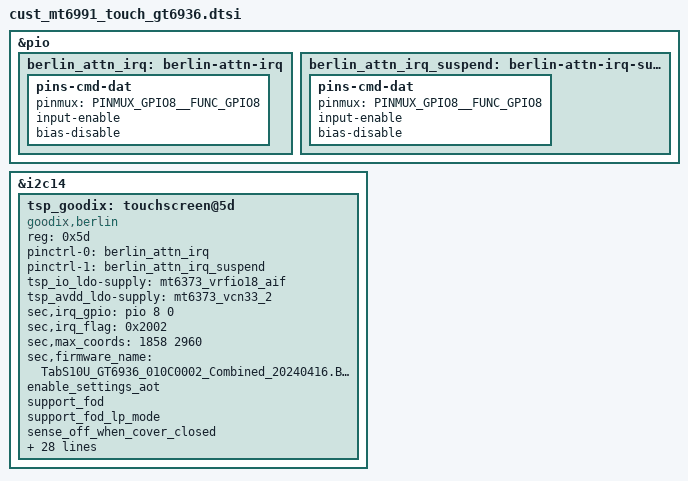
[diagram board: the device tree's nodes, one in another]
// SPDX-License-Identifier: GPL-2.0
/*
 * Copyright (c) 2019 MediaTek Inc.
 */

&pio {
	berlin_attn_irq: berlin-attn-irq {
		pins-cmd-dat {
			pinmux = <PINMUX_GPIO8__FUNC_GPIO8>;
			input-enable;
			bias-disable;
		};
	};

	berlin_attn_irq_suspend: berlin-attn-irq-suspend {
		pins-cmd-dat {
			pinmux = <PINMUX_GPIO8__FUNC_GPIO8>;
			input-enable;
			bias-disable;
		};
	};
};

&i2c14 {
	#address-cells = <1>;
	#size-cells = <0>;
	status = "okay";

	tsp_goodix: touchscreen@5d {
		status = "okay";
		compatible = "goodix,berlin";
		reg = <0x5d>;
		pinctrl-names = "on_state", "off_state";
		pinctrl-0 = <&berlin_attn_irq>;
		pinctrl-1 = <&berlin_attn_irq_suspend>;
		tsp_io_ldo-supply = <&mt6373_vrfio18_aif>;
		tsp_avdd_ldo-supply = <&mt6373_vcn33_2>;
		sec,irq_gpio = <&pio 8 0>;
		sec,irq_flag = <0x2002>; /* IRQF_TRIGGER_FALLING | IRQF_ONESHOT */

		sec,max_coords = <1858 2960>;
		sec,firmware_name = "TabS10U_GT6936_010C0002_Combined_20240416.BIN";

		//sec,lcd_type_unload = <0x801418>; /* this is for stm panel */
		enable_settings_aot;
		support_fod;
		support_fod_lp_mode;
		sense_off_when_cover_closed;
		sec,enable_esd_check;

		sec,ic_type = <1>; //GT6936
		sec,max_drv_num = <52>;
		sec,max_sen_num = <75>;
		sec,drv_map = <75 76 77 78 79 80 81 82
				83 84 85 86 87 88 89 90
				91 92 93 94 95 96 97 98
				99 100 101 102 103 104 105
				106 107 108 109 110 111 112
				113 114 115 116 117 118 119
				120 121 122 123 124 125 126>;
		sec,sen_map = <0 1 2 3 4 5 6 7 8 9 10
				11 12 13 14 15 16 17 18
				19 20 21 22 23 24 25 26
				27 28 29 30 31 32 33 34
				35 36 37 38 39 40 41 42
				43 44 45 46 47 48 49 50
				51 52 53 54 55 56 57 58
				59 60 61 62 63 64 65 66
				67 68 69 70 71 72 73 74>;
		sec,short_test_time_reg = <0x26AE0>;
		sec,short_test_status_reg = <0x20400>;
		sec,short_test_result_reg = <0x20410>;
		sec,drv_drv_reg = <0x2049A>;
		sec,sen_sen_reg = <0x21AF2>;
		sec,drv_sen_reg = <0x248A6>;
		sec,diff_code_reg = <0x269E0>;
		sec,production_test_addr = <0x10FA4>;
		sec,switch_freq_cmd = <0x8A>;
		sec,switch_cfg_cmd = <0xF5>;
		sec,snr_cmd = <0x8B>;
		sec,sensitive_cmd = <0x8C>;

		sec,isp_ram_reg = <0x57000>;
		sec,flash_cmd_reg = <0x13400>;
		sec,isp_buffer_reg = <0x13410>;
		sec,config_data_reg = <0x40000>;
		sec,misctl_reg = <0xD80B>;
		sec,watch_dog_reg = <0xD054>;
		sec,config_id_reg = <0x10076>;
		sec,enable_misctl_val = <0x40>;
	};
};
